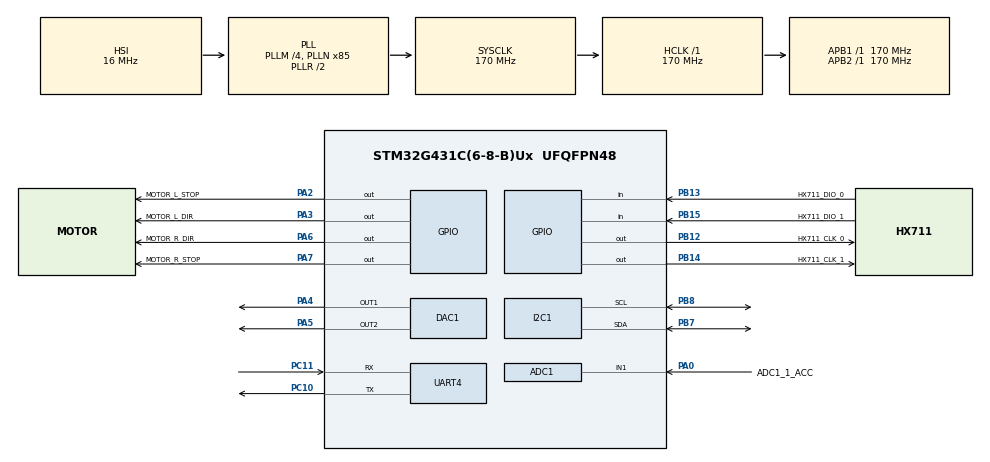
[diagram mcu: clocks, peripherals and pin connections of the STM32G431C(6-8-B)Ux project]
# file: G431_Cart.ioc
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ADC1.Channel-0\#ChannelRegularConversion=ADC_CHANNEL_1
ADC1.ClockPrescaler=ADC_CLOCK_ASYNC_DIV6
ADC1.NbrOfConversionFlag=1
ADC1.OffsetNumber-0\#ChannelRegularConversion=ADC_OFFSET_NONE
ADC1.Rank-0\#ChannelRegularConversion=1
ADC1.SamplingTime-0\#ChannelRegularConversion=ADC_SAMPLETIME_2CYCLES_5
ADC1.master=1
DAC1.DAC_Channel-DAC_OUT2=DAC_CHANNEL_2
Dma.Request0=UART4_TX
Dma.UART4_TX.0.Direction=DMA_MEMORY_TO_PERIPH
Dma.UART4_TX.0.EventEnable=DISABLE
Dma.UART4_TX.0.Instance=DMA1_Channel1
Dma.UART4_TX.0.MemDataAlignment=DMA_MDATAALIGN_BYTE
Dma.UART4_TX.0.MemInc=DMA_MINC_ENABLE
Dma.UART4_TX.0.Mode=DMA_NORMAL
Dma.UART4_TX.0.PeriphDataAlignment=DMA_PDATAALIGN_BYTE
Dma.UART4_TX.0.PeriphInc=DMA_PINC_DISABLE
Dma.UART4_TX.0.Polarity=HAL_DMAMUX_REQ_GEN_RISING
Dma.UART4_TX.0.Priority=DMA_PRIORITY_LOW
Dma.UART4_TX.0.RequestNumber=1
Dma.UART4_TX.0.SignalID=NONE
Dma.UART4_TX.0.SyncEnable=DISABLE
Dma.UART4_TX.0.SyncPolarity=HAL_DMAMUX_SYNC_NO_EVENT
Dma.UART4_TX.0.SyncRequestNumber=1
Dma.UART4_TX.0.SyncSignalID=NONE
FREERTOS.Tasks01=mainTask,0,128,ProcTask,As weak,NULL,Dynamic,NULL,NULL;accrTask,-3,128,SpeedTask,As weak,NULL,Dynamic,NULL,NULL;myTask03,-3,128,StartTask03,As weak,NULL,Dynamic,NULL,NULL;myTask04,-3,128,StartTask04,As weak,NULL,Dynamic,NULL,NULL
FREERTOS.configTOTAL_HEAP_SIZE=4096
I2C1.Timing=0x40B285C2
Mcu.Family=STM32G4
Mcu.Name=STM32G431C(6-8-B)Ux
Mcu.Package=UFQFPN48
NVIC.DMA1_Channel1_IRQn=true\:5\:0\:false\:false\:true\:true\:false\:true\:true
NVIC.PriorityGroup=NVIC_PRIORITYGROUP_4
NVIC.TIM1_TRG_COM_TIM17_IRQn=true\:15\:0\:false\:false\:true\:false\:false\:true\:true
NVIC.TimeBase=TIM1_TRG_COM_TIM17_IRQn
NVIC.TimeBaseIP=TIM17
PA0.GPIO_Label=ADC1_1_ACC
PA0.Mode=IN1-Single-Ended
PA0.Signal=ADC1_IN1
PA13.Mode=Serial_Wire
PA13.Signal=SYS_JTMS-SWDIO
PA14.Mode=Serial_Wire
PA14.Signal=SYS_JTCK-SWCLK
PA2.GPIO_Label=MOTOR_L_STOP
PA2.GPIO_ModeDefaultOutputPP=GPIO_MODE_OUTPUT_OD
PA2.GPIO_PuPd=GPIO_NOPULL
PA2.Signal=GPIO_Output
PA3.GPIO_Label=MOTOR_L_DIR
PA3.GPIO_ModeDefaultOutputPP=GPIO_MODE_OUTPUT_OD
PA3.GPIO_PuPd=GPIO_NOPULL
PA3.Signal=GPIO_Output
PA4.Signal=COMP_DAC11_group
PA5.Signal=COMP_DAC12_group
PA6.GPIO_Label=MOTOR_R_DIR
PA6.GPIO_ModeDefaultOutputPP=GPIO_MODE_OUTPUT_OD
PA6.GPIO_PuPd=GPIO_NOPULL
PA6.Signal=GPIO_Output
PA7.GPIO_Label=MOTOR_R_STOP
PA7.GPIO_ModeDefaultOutputPP=GPIO_MODE_OUTPUT_OD
PA7.GPIO_PuPd=GPIO_NOPULL
PA7.Signal=GPIO_Output
PB12.GPIO_Label=HX711_CLK_0
PB12.PinState=GPIO_PIN_RESET
PB12.Signal=GPIO_Output
PB13.GPIO_Label=HX711_DIO_0
PB13.Signal=GPIO_Input
PB14.GPIO_Label=HX711_CLK_1
PB14.Signal=GPIO_Output
PB15.GPIO_Label=HX711_DIO_1
PB15.Signal=GPIO_Input
PB7.Mode=I2C
PB7.Signal=I2C1_SDA
PB8-BOOT0.Mode=I2C
PB8-BOOT0.Signal=I2C1_SCL
PC10.Mode=Asynchronous
PC10.Signal=UART4_TX
PC11.Mode=Asynchronous
PC11.Signal=UART4_RX
ProjectManager.HeapSize=0x200
ProjectManager.StackSize=0x400
ProjectManager.TargetToolchain=MDK-ARM V5.32
RCC.ADC12Freq_Value=170000000
RCC.AHBFreq_Value=170000000
RCC.APB1Freq_Value=170000000
RCC.APB1TimFreq_Value=170000000
RCC.APB2Freq_Value=170000000
RCC.APB2TimFreq_Value=170000000
RCC.CortexFreq_Value=170000000
RCC.EXTERNAL_CLOCK_VALUE=12288000
RCC.HCLKFreq_Value=170000000
RCC.HSE_VALUE=8000000
RCC.HSI48_VALUE=48000000
RCC.HSI_VALUE=16000000
RCC.LSE_VALUE=32768
RCC.PLLM=RCC_PLLM_DIV4
RCC.PLLN=85
RCC.SYSCLKFreq_VALUE=170000000
RCC.SYSCLKSource=RCC_SYSCLKSOURCE_PLLCLK
RCC.USBFreq_Value=170000000
RCC.VCOOutputFreq_Value=340000000
SH.COMP_DAC11_group.0=DAC1_OUT1,DAC_OUT1
SH.COMP_DAC12_group.0=DAC1_OUT2,DAC_OUT2
VP_FREERTOS_VS_CMSIS_V1.Mode=CMSIS_V1
VP_SYS_VS_DBSignals.Mode=DisableDeadBatterySignals
VP_SYS_VS_tim17.Mode=TIM17
board=custom

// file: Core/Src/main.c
/* USER CODE BEGIN Header */
/**
  ******************************************************************************
  * @file           : main.c
  * @brief          : Main program body
  ******************************************************************************
  * @attention
  *
  * Copyright (c) 2024 STMicroelectronics.
  * All rights reserved.
  *
  * This software is licensed under terms that can be found in the LICENSE file
  * in the root directory of this software component.
  * If no LICENSE file comes with this software, it is provided AS-IS.
  *
  ******************************************************************************
  */
/* USER CODE END Header */
#include "main.h"
#include "cmsis_os.h"
#include "adc.h"
#include "dac.h"
#include "dma.h"
#include "i2c.h"
#include "usart.h"
#include "gpio.h"

/* USER CODE BEGIN Includes */
#include "proj.h"
/* USER CODE END Includes */

void SystemClock_Config(void);
void MX_FREERTOS_Init(void);

int main(void)
{

  /* MCU Configuration--------------------------------------------------------*/

  /* Reset of all peripherals, Initializes the Flash interface and the Systick. */
  HAL_Init();

  /* Configure the system clock */
  SystemClock_Config();

  /* Initialize all configured peripherals */
  MX_GPIO_Init();
  MX_DMA_Init();
  MX_ADC1_Init();
  MX_UART4_Init();
  MX_DAC1_Init();
  MX_I2C1_Init();
  /* USER CODE BEGIN 2 */
  Proj_Init();
  /* USER CODE END 2 */

  /* Call init function for freertos objects (in cmsis_os2.c) */
  MX_FREERTOS_Init();

  /* Start scheduler */
  osKernelStart();

  /* We should never get here as control is now taken by the scheduler */

  /* Infinite loop */
  /* USER CODE BEGIN WHILE */
  while (1)
  {
    Proj_Proc();
    /* USER CODE END WHILE */

  }
}

void SystemClock_Config(void)
{
  RCC_OscInitTypeDef RCC_OscInitStruct = {0};
  RCC_ClkInitTypeDef RCC_ClkInitStruct = {0};

  /** Configure the main internal regulator output voltage
  */
  HAL_PWREx_ControlVoltageScaling(PWR_REGULATOR_VOLTAGE_SCALE1_BOOST);

  /** Initializes the RCC Oscillators according to the specified parameters
  * in the RCC_OscInitTypeDef structure.
  */
  RCC_OscInitStruct.OscillatorType = RCC_OSCILLATORTYPE_HSI;
  RCC_OscInitStruct.HSIState = RCC_HSI_ON;
  RCC_OscInitStruct.HSICalibrationValue = RCC_HSICALIBRATION_DEFAULT;
  RCC_OscInitStruct.PLL.PLLState = RCC_PLL_ON;
  RCC_OscInitStruct.PLL.PLLSource = RCC_PLLSOURCE_HSI;
  RCC_OscInitStruct.PLL.PLLM = RCC_PLLM_DIV4;
  RCC_OscInitStruct.PLL.PLLN = 85;
  RCC_OscInitStruct.PLL.PLLP = RCC_PLLP_DIV2;
  RCC_OscInitStruct.PLL.PLLQ = RCC_PLLQ_DIV2;
  RCC_OscInitStruct.PLL.PLLR = RCC_PLLR_DIV2;
  if (HAL_RCC_OscConfig(&RCC_OscInitStruct) != HAL_OK)
  {
    Error_Handler();
  }

  /** Initializes the CPU, AHB and APB buses clocks
  */
  RCC_ClkInitStruct.ClockType = RCC_CLOCKTYPE_HCLK|RCC_CLOCKTYPE_SYSCLK
                              |RCC_CLOCKTYPE_PCLK1|RCC_CLOCKTYPE_PCLK2;
  RCC_ClkInitStruct.SYSCLKSource = RCC_SYSCLKSOURCE_PLLCLK;
  RCC_ClkInitStruct.AHBCLKDivider = RCC_SYSCLK_DIV1;
  RCC_ClkInitStruct.APB1CLKDivider = RCC_HCLK_DIV1;
  RCC_ClkInitStruct.APB2CLKDivider = RCC_HCLK_DIV1;

  if (HAL_RCC_ClockConfig(&RCC_ClkInitStruct, FLASH_LATENCY_4) != HAL_OK)
  {
    Error_Handler();
  }
}

void HAL_TIM_PeriodElapsedCallback(TIM_HandleTypeDef *htim)
{
  if (htim->Instance == TIM17) {
    HAL_IncTick();
  }
}

void Error_Handler(void)
{
  __disable_irq();
  while (1)
  {
  }
}

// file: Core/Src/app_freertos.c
/* USER CODE BEGIN Header */
/**
  ******************************************************************************
  * File Name          : app_freertos.c
  * Description        : Code for freertos applications
  ******************************************************************************
  * @attention
  *
  * Copyright (c) 2024 STMicroelectronics.
  * All rights reserved.
  *
  * This software is licensed under terms that can be found in the LICENSE file
  * in the root directory of this software component.
  * If no LICENSE file comes with this software, it is provided AS-IS.
  *
  ******************************************************************************
  */
/* USER CODE END Header */

#include "FreeRTOS.h"
#include "task.h"
#include "main.h"
#include "cmsis_os.h"

osThreadId mainTaskHandle;
osThreadId accrTaskHandle;
osThreadId myTask03Handle;
osThreadId myTask04Handle;

void ProcTask(void const * argument);
void SpeedTask(void const * argument);
void StartTask03(void const * argument);
void StartTask04(void const * argument);

void MX_FREERTOS_Init(void); /* (MISRA C 2004 rule 8.1) */

void MX_FREERTOS_Init(void) {

  /* Create the thread(s) */
  /* definition and creation of mainTask */
  osThreadDef(mainTask, ProcTask, osPriorityNormal, 0, 128);
  mainTaskHandle = osThreadCreate(osThread(mainTask), NULL);

  /* definition and creation of accrTask */
  osThreadDef(accrTask, SpeedTask, osPriorityIdle, 0, 128);
  accrTaskHandle = osThreadCreate(osThread(accrTask), NULL);

  /* definition and creation of myTask03 */
  osThreadDef(myTask03, StartTask03, osPriorityIdle, 0, 128);
  myTask03Handle = osThreadCreate(osThread(myTask03), NULL);

  /* definition and creation of myTask04 */
  osThreadDef(myTask04, StartTask04, osPriorityIdle, 0, 128);
  myTask04Handle = osThreadCreate(osThread(myTask04), NULL);

}

__weak void ProcTask(void const * argument)
{
  for(;;)
  {
    osDelay(1);
  }
}

__weak void SpeedTask(void const * argument)
{
  for(;;)
  {
    osDelay(1);
  }
}

__weak void StartTask03(void const * argument)
{
  for(;;)
  {
    osDelay(1);
  }
}

__weak void StartTask04(void const * argument)
{
  for(;;)
  {
    osDelay(1);
  }
}
